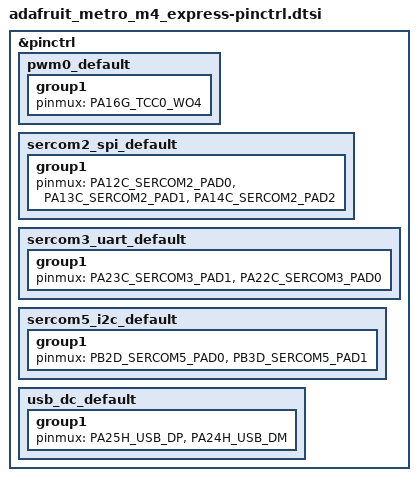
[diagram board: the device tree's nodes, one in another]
/*
 * Copyright (c) 2022, Gerson Fernando Budke <nandojve@gmail.com>
 * Copyright (c) 2022 Frank Dischner <frank.dischner@gmail.com>
 * SPDX-License-Identifier: Apache-2.0
 */

#include <dt-bindings/pinctrl/samd51j-pinctrl.h>

&pinctrl {
	pwm0_default: pwm0_default {
		group1 {
			pinmux = <PA16G_TCC0_WO4>;
		};
	};

	sercom2_spi_default: sercom2_spi_default {
		group1 {
			pinmux = <PA12C_SERCOM2_PAD0>,
				 <PA13C_SERCOM2_PAD1>,
				 <PA14C_SERCOM2_PAD2>;
		};
	};

	sercom3_uart_default: sercom3_uart_default {
		group1 {
			pinmux = <PA23C_SERCOM3_PAD1>,
				 <PA22C_SERCOM3_PAD0>;
		};
	};

	sercom5_i2c_default: sercom5_i2c_default {
		group1 {
			pinmux = <PB2D_SERCOM5_PAD0>,
				 <PB3D_SERCOM5_PAD1>;
		};
	};

	usb_dc_default: usb_dc_default {
		group1 {
			pinmux = <PA25H_USB_DP>,
				 <PA24H_USB_DM>;
		};
	};
};
